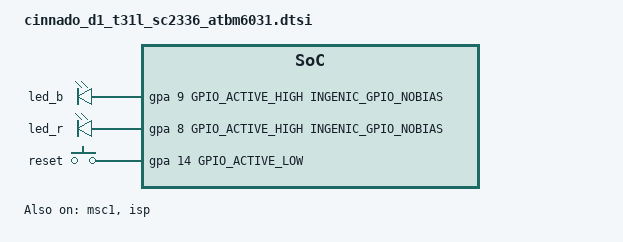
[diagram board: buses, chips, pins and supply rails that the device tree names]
// Cinnado D1 (T31L, SC2336, ATBM6031) per-board GPIO definitions.
// Injected into the kernel 4.4+ device tree; ignored on 3.10.

#include <dt-bindings/gpio/gpio.h>
#include <dt-bindings/input/input.h>
#include <dt-bindings/pinctrl/ingenic-pinctrl.h>

/ {
	gpio-leds {
		compatible = "gpio-leds";

		led_b {
			label = "led_b";
			gpios = <&gpa 9 GPIO_ACTIVE_HIGH INGENIC_GPIO_NOBIAS>;
			default-state = "off";
		};

		led_r {
			label = "led_r";
			gpios = <&gpa 8 GPIO_ACTIVE_HIGH INGENIC_GPIO_NOBIAS>;
			default-state = "off";
		};
	};
};

/* Card detect; the family tree carries the reference pin. */
&msc0 {
	ingenic,cd-gpios = <&gpb 18 GPIO_ACTIVE_LOW INGENIC_GPIO_PULLUP>;
};

/* SDIO WLAN (atbm6031) hangs off MMC1 on PB8-11/PB13-14; the family tree
   disables msc1 because it uses MSC0 for the card slot. The SoC node uses
   the mainline jz4740_mmc compatible, which cannot bring up this SDIO card;
   select the Ingenic vendor MSC driver instead, with the same setup as the
   working 5.15 board (clock kept running, 4-bit, soldered module). */
&msc1 {
	status = "okay";
	compatible = "ingenic,mmc";
	pinctrl-names = "default", "active";
	pinctrl-0 = <&msc1_pb>;
	pinctrl-1 = <&msc1_pb>;
	ingenic,sdio_clk = <1>;
	bus-width = <4>;
	max-frequency = <50000000>;
	non-removable;
};

/* This board is WiFi-only, but the generic T31 tree enables the MAC, whose
   RMII pinmux claims PB6-14 - the same pins MSC1/SDIO needs. Disable it. */
&mac {
	status = "disabled";
};

/* The reference tree enables I2C1 on PB25/PB26 (i2c1_pb); this board wires
   those pins to the IR-CUT (gpio.ircut = "57 58"), so i2c1 must not hold the
   pinmux or the IR-CUT GPIO request logs a pinmux conflict. */
&i2c1 {
	status = "disabled";
};

/ {
	gpio-keys {
		compatible = "gpio-keys";
		label = "gpio-keys";

		reset {
			label = "reset";
			linux,code = <KEY_ENTER>;
			gpios = <&gpa 14 GPIO_ACTIVE_LOW INGENIC_GPIO_PULLUP>;
		};
	};
};

/* The SoC t31.dtsi ships the ISP disabled; the vendor tx-isp driver must
   probe before any sensor module can register with it. */
&isp {
	status = "okay";
};
